# nrf52840 register map
Vendor: Nordic Semiconductor; Series: nrf52; File version: 1
CPU: CM4 r0p1, little endian, MPU, FPU, 3 interrupt priority bits
Registers are 32-bit, read-write, reset 0x0 unless marked. A register's access mark holds for its fields unless they carry their own. Offsets are from the block's base; [hi:lo] are bit positions; lines under a group give offsets from that group; 'fields as' and 'values as' point back to an identical list.

## UARTE0 — UART with EasyDMA 0
Base 0x40002000; alternate view of UART0
Same registers: UARTE1 0x40028000
0x00 TASKS_STARTRX wo — Start UART receiver
  [0] TASKS_STARTRX
0x04 TASKS_STOPRX wo — Stop UART receiver
  [0] TASKS_STOPRX
0x08 TASKS_STARTTX wo — Start UART transmitter
  [0] TASKS_STARTTX
0x0C TASKS_STOPTX wo — Stop UART transmitter
  [0] TASKS_STOPTX
0x2C TASKS_FLUSHRX wo — Flush RX FIFO into RX buffer
  [0] TASKS_FLUSHRX
0x100 EVENTS_CTS — CTS is activated (set low). Clear To Send.
  [0] EVENTS_CTS
0x104 EVENTS_NCTS — CTS is deactivated (set high). Not Clear To Send.
  [0] EVENTS_NCTS
0x108 EVENTS_RXDRDY — Data received in RXD (but potentially not yet transferred to Data RAM)
  [0] EVENTS_RXDRDY
0x110 EVENTS_ENDRX — Receive buffer is filled up
  [0] EVENTS_ENDRX
0x11C EVENTS_TXDRDY — Data sent from TXD
  [0] EVENTS_TXDRDY
0x120 EVENTS_ENDTX — Last TX byte transmitted
  [0] EVENTS_ENDTX
0x124 EVENTS_ERROR — Error detected
  [0] EVENTS_ERROR
0x144 EVENTS_RXTO — Receiver timeout
  [0] EVENTS_RXTO
0x14C EVENTS_RXSTARTED — UART receiver has started
  [0] EVENTS_RXSTARTED
0x150 EVENTS_TXSTARTED — UART transmitter has started
  [0] EVENTS_TXSTARTED
0x158 EVENTS_TXSTOPPED — Transmitter stopped
  [0] EVENTS_TXSTOPPED
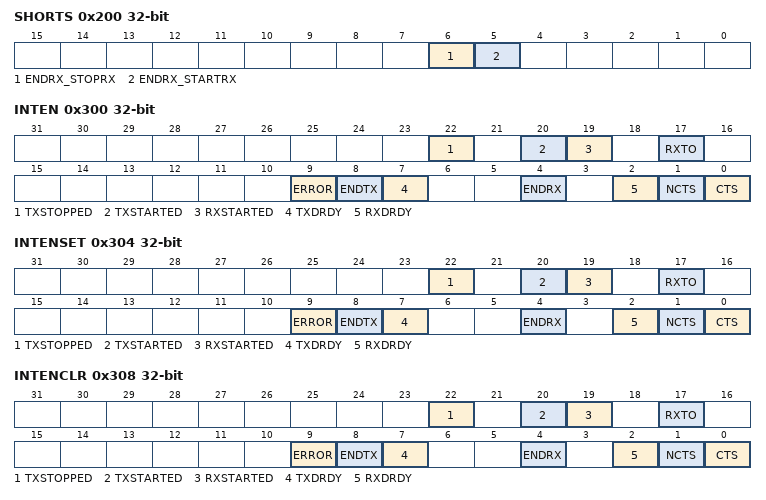
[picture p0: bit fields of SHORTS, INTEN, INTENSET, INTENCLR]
0x200 SHORTS — Shortcut register
  [6] ENDRX_STOPRX — Shortcut between ENDRX event and STOPRX task
    0=Disabled (Disable shortcut); 1=Enabled (Enable shortcut)
  [5] ENDRX_STARTRX — Shortcut between ENDRX event and STARTRX task
    0=Disabled (Disable shortcut); 1=Enabled (Enable shortcut)
0x300 INTEN — Enable or disable interrupt
  [all] fields
    0=Disabled; 1=Enabled
  [22] TXSTOPPED — Enable or disable interrupt for TXSTOPPED event
  [20] TXSTARTED — Enable or disable interrupt for TXSTARTED event
  [19] RXSTARTED — Enable or disable interrupt for RXSTARTED event
  [17] RXTO — Enable or disable interrupt for RXTO event
  [9] ERROR — Enable or disable interrupt for ERROR event
  [8] ENDTX — Enable or disable interrupt for ENDTX event
  [7] TXDRDY — Enable or disable interrupt for TXDRDY event
  [4] ENDRX — Enable or disable interrupt for ENDRX event
  [2] RXDRDY — Enable or disable interrupt for RXDRDY event
  [1] NCTS — Enable or disable interrupt for NCTS event
  [0] CTS — Enable or disable interrupt for CTS event
0x304 INTENSET — Enable interrupt
  [all] fields
    on read: 0=Disabled (Read: Disabled); 1=Enabled (Read: Enabled) | on write: 1=Set (Enable)
  [22] TXSTOPPED — Write '1' to enable interrupt for TXSTOPPED event
  [20] TXSTARTED — Write '1' to enable interrupt for TXSTARTED event
  [19] RXSTARTED — Write '1' to enable interrupt for RXSTARTED event
  [17] RXTO — Write '1' to enable interrupt for RXTO event
  [9] ERROR — Write '1' to enable interrupt for ERROR event
  [8] ENDTX — Write '1' to enable interrupt for ENDTX event
  [7] TXDRDY — Write '1' to enable interrupt for TXDRDY event
  [4] ENDRX — Write '1' to enable interrupt for ENDRX event
  [2] RXDRDY — Write '1' to enable interrupt for RXDRDY event
  [1] NCTS — Write '1' to enable interrupt for NCTS event
  [0] CTS — Write '1' to enable interrupt for CTS event
0x308 INTENCLR — Disable interrupt
  [all] fields
    on read: 0=Disabled (Read: Disabled); 1=Enabled (Read: Enabled) | on write: 1=Clear (Disable)
  [22] TXSTOPPED — Write '1' to disable interrupt for TXSTOPPED event
  [20] TXSTARTED — Write '1' to disable interrupt for TXSTARTED event
  [19] RXSTARTED — Write '1' to disable interrupt for RXSTARTED event
  [17] RXTO — Write '1' to disable interrupt for RXTO event
  [9] ERROR — Write '1' to disable interrupt for ERROR event
  [8] ENDTX — Write '1' to disable interrupt for ENDTX event
  [7] TXDRDY — Write '1' to disable interrupt for TXDRDY event
  [4] ENDRX — Write '1' to disable interrupt for ENDRX event
  [2] RXDRDY — Write '1' to disable interrupt for RXDRDY event
  [1] NCTS — Write '1' to disable interrupt for NCTS event
  [0] CTS — Write '1' to disable interrupt for CTS event
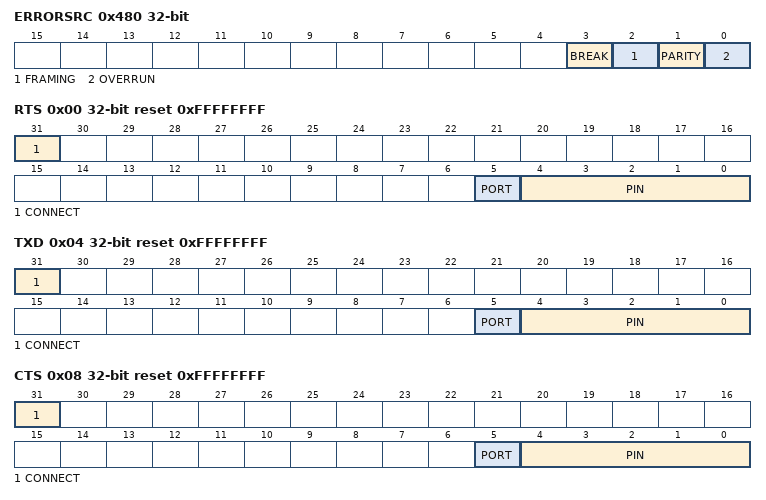
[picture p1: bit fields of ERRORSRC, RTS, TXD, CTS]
0x480 ERRORSRC write-1-clears — Error source Note : this register is read / write one to clear.
  [all] fields
    on read: 0=NotPresent (Read: error not present); 1=Present (Read: error present)
  [3] BREAK — Break condition
  [2] FRAMING — Framing error occurred
  [1] PARITY — Parity error
  [0] OVERRUN — Overrun error
0x500 ENABLE — Enable UART
  [3:0] ENABLE — Enable or disable UARTE
    0=Disabled (Disable UARTE); 8=Enabled (Enable UARTE)
0x508 PSEL group — Unspecified
  0x00 RTS reset 0xFFFFFFFF — Pin select for RTS signal
    [31] CONNECT — Connection
      1=Disconnected; 0=Connected
    [5] PORT — Port number
    [4:0] PIN — Pin number
  0x04 TXD reset 0xFFFFFFFF — Pin select for TXD signal
    fields as PSEL.RTS
  0x08 CTS reset 0xFFFFFFFF — Pin select for CTS signal
    fields as PSEL.RTS
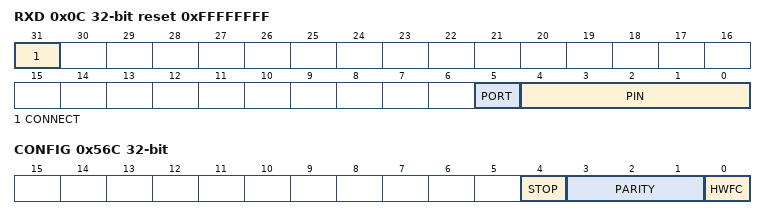
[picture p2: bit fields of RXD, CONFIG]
  0x0C RXD reset 0xFFFFFFFF — Pin select for RXD signal
    fields as PSEL.RTS
0x524 BAUDRATE reset 0x4000000 — Baud rate. Accuracy depends on the HFCLK source selected.
  [31:0] BAUDRATE
    0x4F000=Baud1200 (1200 baud (actual rate: 1205)); 0x9D000=Baud2400 (2400 baud (actual rate: 2396)); 0x13B000=Baud4800 (4800 baud (actual rate: 4808)); 0x275000=Baud9600 (9600 baud (actual rate: 9598)); 0x3AF000=Baud14400 (14400 baud (actual rate: 14401)); 0x4EA000=Baud19200 (19200 baud (actual rate: 19208)); 0x75C000=Baud28800 (28800 baud (actual rate: 28777)); 0x800000=Baud31250 (31250 baud); 0x9D0000=Baud38400 (38400 baud (actual rate: 38369)); 0xE50000=Baud56000 (56000 baud (actual rate: 55944)); 0xEB0000=Baud57600 (57600 baud (actual rate: 57554)); 0x13A9000=Baud76800 (76800 baud (actual rate: 76923)); 0x1D60000=Baud115200 (115200 baud (actual rate: 115108)); 0x3B00000=Baud230400 (230400 baud (actual rate: 231884)); 0x4000000=Baud250000 (250000 baud); 0x7400000=Baud460800 (460800 baud (actual rate: 457143)); 0xF000000=Baud921600 (921600 baud (actual rate: 941176)); 0x10000000=Baud1M (1Mega baud)
0x534 RXD group — RXD EasyDMA channel
  0x00 PTR — Data pointer
  0x04 MAXCNT — Maximum number of bytes in receive buffer
    [15:0] MAXCNT
  0x08 AMOUNT ro — Number of bytes transferred in the last transaction
    [15:0] AMOUNT
0x544 TXD group — TXD EasyDMA channel
  0x00 PTR — Data pointer
  0x04 MAXCNT — Maximum number of bytes in transmit buffer
    [15:0] MAXCNT
  0x08 AMOUNT ro — Number of bytes transferred in the last transaction
    [15:0] AMOUNT
0x56C CONFIG — Configuration of parity and hardware flow control
  [4] STOP — Stop bits
    0=One (One stop bit); 1=Two (Two stop bits)
  [3:1] PARITY
    0=Excluded (Exclude parity bit); 7=Included (Include even parity bit)
  [0] HWFC — Hardware flow control
    0=Disabled; 1=Enabled
